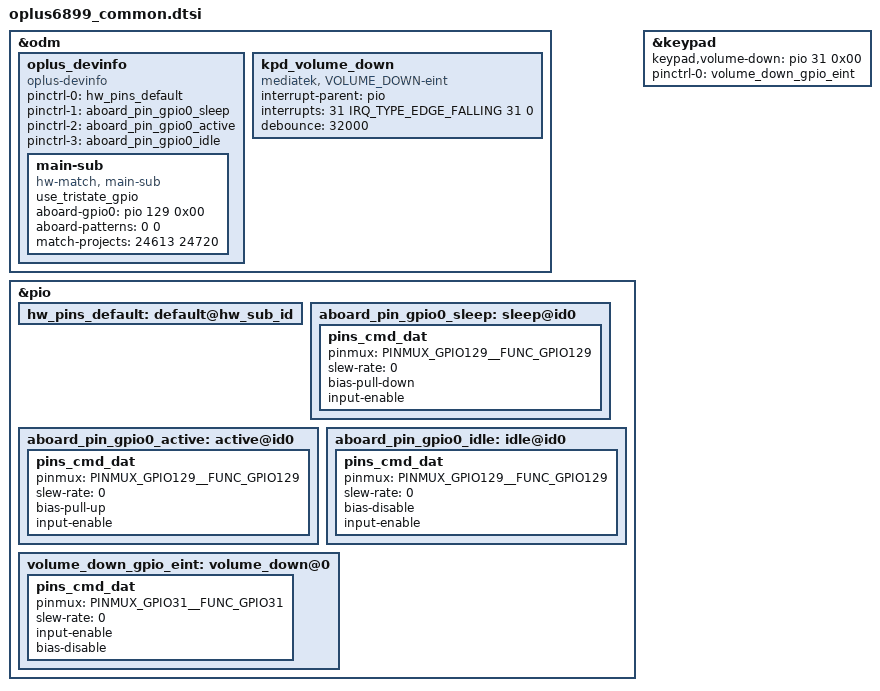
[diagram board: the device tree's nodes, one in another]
// SPDX-License-Identifier: GPL-2.0
/*
 * Copyright (c) 2024 MediaTek Inc.
 */

#include <dt-bindings/pinctrl/mt6899-pinfunc.h>

&odm {

        oplus_devinfo:oplus_devinfo {
                compatible = "oplus-devinfo";
                pinctrl-names = "default", "aboard_gpio0_sleep", "aboard_gpio0_active", "aboard_gpio0_idle";
                pinctrl-0 = <&hw_pins_default>;
                pinctrl-1 = <&aboard_pin_gpio0_sleep>;
                pinctrl-2 = <&aboard_pin_gpio0_active>;
                pinctrl-3 = <&aboard_pin_gpio0_idle>;
                main-sub {
                        use_tristate_gpio;
                        compatible = "hw-match, main-sub";
                        aboard-gpio0 = <&pio 129 0x00>;
                        aboard-patterns = <0 0>;        //0[high-resistance] 1[pull-down] 2[pull-up]
                        //main board
                        match-projects = <24613 24720>;
                };
        };

};

&pio{
        hw_pins_default:default@hw_sub_id {
	};

        aboard_pin_gpio0_sleep:sleep@id0 {
		pins_cmd_dat {
			pinmux = <PINMUX_GPIO129__FUNC_GPIO129>;
			slew-rate = <0>;
			bias-pull-down;
			input-enable;
		};
	};

	aboard_pin_gpio0_active:active@id0 {
		pins_cmd_dat {
			pinmux = <PINMUX_GPIO129__FUNC_GPIO129>;
			slew-rate = <0>;
			bias-pull-up;
			input-enable;
		};
	};

	aboard_pin_gpio0_idle:idle@id0 {
		pins_cmd_dat {
			pinmux = <PINMUX_GPIO129__FUNC_GPIO129>;
			slew-rate = <0>;
			bias-disable;
			input-enable;
		};
	};
};
&keypad {
        keypad,volume-down = <&pio 31 0x00>;
        pinctrl-names = "volume_down_as_int";
        pinctrl-0 = <&volume_down_gpio_eint>;
        status = "okay";
};

&pio {
        volume_down_gpio_eint:volume_down@0{
                pins_cmd_dat {
                        pinmux = <PINMUX_GPIO31__FUNC_GPIO31>;
                        slew-rate = <0>;  /*direction 0:in, 1:out*/
                        input-enable;
                        bias-disable;
                };
        };
};

&odm {
        kpd_volume_down:kpd_volume_down {
                compatible = "mediatek, VOLUME_DOWN-eint";
                interrupt-parent = <&pio>;
                interrupts = <31 IRQ_TYPE_EDGE_FALLING 31 0>;
                debounce = <32000>;
                status = "okay";
        };
};
